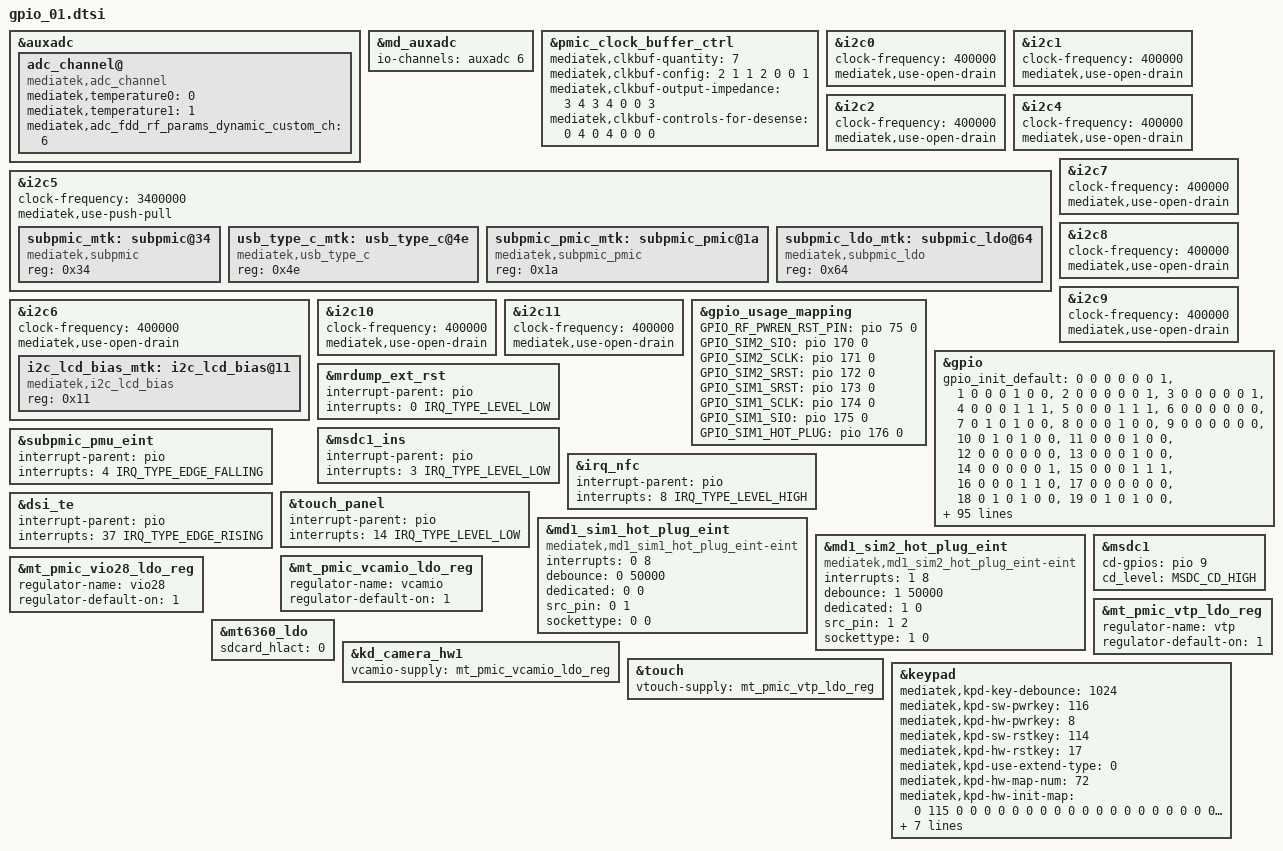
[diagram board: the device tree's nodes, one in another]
/*
 * Mediatek's mt6877 SoC device tree source
 *
 * Copyright (C) 2021 MediaTek Inc.
 *
 * This program is free software; you can redistribute it and/or modify
 * it under the terms of the GNU General Public License version 2 as
 * published by the Free Software Foundation.
 *
 * This program is distributed in the hope that it will be useful,
 * but WITHOUT ANY WARRANTY; without even the implied warranty of
 * MERCHANTABILITY or FITNESS FOR A PARTICULAR PURPOSE.
 * See http://www.gnu.org/licenses/gpl-2.0.html for more details.
 */
/*
 * Generated by MTK SP DrvGen Version: 3.5.160809 for MT6877.
 * 2021-09-27 17:35:26
 * Do Not Modify The File.
 * Copyright Mediatek Inc. (c) 2021.
 */

/*************************
 * ADC DTSI File
 *************************/

&auxadc {
	adc_channel@ {
		compatible = "mediatek,adc_channel";
		mediatek,temperature0 = <0>;
		mediatek,temperature1 = <1>;
		mediatek,adc_fdd_rf_params_dynamic_custom_ch = <6>;
		status = "okay";
	};
};
&md_auxadc {
	io-channels = <&auxadc 6>;
};


/*************************
 * CLK_BUF DTSI File
 *************************/

&pmic_clock_buffer_ctrl {
	mediatek,clkbuf-quantity = <7>;
	mediatek,clkbuf-config = <2 1 1 2 0 0 1>;
	mediatek,clkbuf-output-impedance = <3 4 3 4 0 0 3>;
	mediatek,clkbuf-controls-for-desense = <0 4 0 4 0 0 0>;
	status = "okay";
};


/*************************
 * I2C DTSI File
 *************************/

&i2c0 {
	#address-cells = <1>;
	#size-cells = <0>;
	clock-frequency = <400000>;
	mediatek,use-open-drain;
};

&i2c1 {
	#address-cells = <1>;
	#size-cells = <0>;
	clock-frequency = <400000>;
	mediatek,use-open-drain;
};

&i2c2 {
	#address-cells = <1>;
	#size-cells = <0>;
	clock-frequency = <400000>;
	mediatek,use-open-drain;
	// camera_main_two_mtk:camera_main_two@10 {
	// 	compatible = "mediatek,camera_main_two";
	// 	reg = <0x10>;
	// 	status = "okay";
	// };

	// camera_main_three_mtk:camera_main_three@10 {
	// 	compatible = "mediatek,camera_main_three";
	// 	reg = <0x10>;
	// 	status = "okay";
	// };

	// camera_main_three_af_mtk:camera_main_three_af@0c {
	// 	compatible = "mediatek,camera_main_three_af";
	// 	reg = <0x0c>;
	// 	status = "okay";
	// };

};

&i2c4 {
	#address-cells = <1>;
	#size-cells = <0>;
	clock-frequency = <400000>;
	mediatek,use-open-drain;
	// camera_sub_mtk:camera_sub@1a {
	// 	compatible = "mediatek,camera_sub";
	// 	reg = <0x1a>;
	// 	status = "okay";
	// };

	// camera_main_two_af_mtk:camera_main_two_af@0c {
	// 	compatible = "mediatek,camera_main_two_af";
	// 	reg = <0x0c>;
	// 	status = "okay";
	// };

};

&i2c5 {
	#address-cells = <1>;
	#size-cells = <0>;
	clock-frequency = <3400000>;
	mediatek,use-push-pull;
	subpmic_mtk:subpmic@34 {
		compatible = "mediatek,subpmic";
		reg = <0x34>;
		status = "okay";
	};

	usb_type_c_mtk:usb_type_c@4e {
		compatible = "mediatek,usb_type_c";
		reg = <0x4e>;
		status = "okay";
	};

	subpmic_pmic_mtk:subpmic_pmic@1a {
		compatible = "mediatek,subpmic_pmic";
		reg = <0x1a>;
		status = "okay";
	};

	subpmic_ldo_mtk:subpmic_ldo@64 {
		compatible = "mediatek,subpmic_ldo";
		reg = <0x64>;
		status = "okay";
	};

};

&i2c6 {
	#address-cells = <1>;
	#size-cells = <0>;
	clock-frequency = <400000>;
	mediatek,use-open-drain;
	i2c_lcd_bias_mtk:i2c_lcd_bias@11 {
		compatible = "mediatek,i2c_lcd_bias";
		reg = <0x11>;
		status = "okay";
	};

};

&i2c7 {
	#address-cells = <1>;
	#size-cells = <0>;
	clock-frequency = <400000>;
	mediatek,use-open-drain;
};

&i2c8 {
	#address-cells = <1>;
	#size-cells = <0>;
	clock-frequency = <400000>;
	mediatek,use-open-drain;
	// camera_main_mtk:camera_main@1a {
	// 	compatible = "mediatek,camera_main";
	// 	reg = <0x1a>;
	// 	status = "okay";
	// };

	// camera_main_af_mtk:camera_main_af@0e {
	// 	compatible = "mediatek,camera_main_af";
	// 	reg = <0x0e>;
	// 	status = "okay";
	// };

};

&i2c9 {
	#address-cells = <1>;
	#size-cells = <0>;
	clock-frequency = <400000>;
	mediatek,use-open-drain;
};

&i2c10 {
	#address-cells = <1>;
	#size-cells = <0>;
	clock-frequency = <400000>;
	mediatek,use-open-drain;
};

&i2c11 {
	#address-cells = <1>;
	#size-cells = <0>;
	clock-frequency = <400000>;
	mediatek,use-open-drain;
};



/*************************
 * GPIO DTSI File
 *************************/

&gpio_usage_mapping {
	GPIO_RF_PWREN_RST_PIN = <&pio 75 0>;
	GPIO_SIM2_SIO = <&pio 170 0>;
	GPIO_SIM2_SCLK = <&pio 171 0>;
	GPIO_SIM2_SRST = <&pio 172 0>;
	GPIO_SIM1_SRST = <&pio 173 0>;
	GPIO_SIM1_SCLK = <&pio 174 0>;
	GPIO_SIM1_SIO = <&pio 175 0>;
	GPIO_SIM1_HOT_PLUG = <&pio 176 0>;
};

&gpio{
	gpio_init_default = <0 0 0 0 0 0 1>,
		<1 0 0 0 1 0 0>,	/* EL_ON1_DET */
		<2 0 0 0 0 0 1>,
		<3 0 0 0 0 0 1>,
		<4 0 0 0 1 1 1>,
		<5 0 0 0 1 1 1>,
		<6 0 0 0 0 0 0>,
		<7 0 1 0 1 0 0>,
		<8 0 0 0 1 0 0>,	/* FG_ERR */
		<9 0 0 0 0 0 0>,
		<10 0 1 0 1 0 0>,
		<11 0 0 0 1 0 0>,
		<12 0 0 0 0 0 0>,
		<13 0 0 0 1 0 0>,
		<14 0 0 0 0 0 1>,
		<15 0 0 0 1 1 1>,
		<16 0 0 0 1 1 0>,
		<17 0 0 0 0 0 0>,
		<18 0 1 0 1 0 0>,
		<19 0 1 0 1 0 0>,
		<20 0 1 0 1 0 0>,
		<21 0 0 0 1 1 1>,
		<22 0 0 0 1 1 1>,
		<23 7 0 0 1 0 0>,
		<24 0 0 0 1 0 0>,
		<25 0 0 0 1 0 0>,
		<26 0 0 0 1 0 0>,
		<27 0 0 0 1 0 0>,
		<28 0 0 0 1 0 0>,
		<29 0 0 0 1 0 0>,
		<30 0 0 0 1 0 0>,
		<31 0 0 0 1 0 0>,
		<32 0 0 0 1 0 0>,
		<33 0 0 0 1 0 0>,
		<34 0 0 0 1 0 0>,
		<35 0 0 0 1 0 0>,
		<36 1 0 0 1 1 1>,
		<37 1 0 0 1 1 1>,
		<38 0 0 0 1 0 0>,
		<39 1 0 0 1 0 1>,
		<40 0 1 0 0 2 0>,	/* OCTA_RST_N */
		<41 1 0 0 0 0 1>,
		<42 1 0 0 0 0 1>,
		<43 1 0 0 1 0 1>,
		<44 1 0 0 1 0 1>,
		<45 1 0 0 1 0 1>,
		<46 1 0 0 0 0 0>,
		<47 1 0 0 0 0 0>,
		<48 1 0 0 0 0 0>,
		<49 1 0 0 0 0 0>,
		<50 1 0 0 1 0 0>,
		<51 1 0 0 1 0 0>,
		<52 1 0 0 1 0 0>,
		<53 1 0 0 1 0 0>,
		<54 1 0 0 1 0 1>,
		<55 1 0 0 1 0 0>,
		<56 1 0 0 1 0 0>,
		<57 1 0 0 1 0 0>,
		<58 1 0 0 1 0 0>,
		<59 1 0 0 1 0 0>,
		<60 1 0 0 0 0 1>,
		<61 1 0 0 0 0 1>,
		<62 0 0 0 1 0 0>,
		<63 0 0 0 1 0 0>,
		<64 1 0 0 1 1 1>,
		<65 1 0 0 1 1 1>,
		<66 1 0 0 1 0 1>,
		<67 1 0 0 1 0 1>,
		<68 1 0 0 0 0 0>,  /*MIPI_ANT2_SCLK*/
		<69 1 0 0 1 0 0>,  /*MIPI_ANT2_SDATA*/
		<70 1 0 0 1 0 1>,
		<71 0 0 0 0 0 0>,  /*CABLE_DET_MAIN1*/
		<72 0 0 0 0 0 0>,  /*CABLE_DET_MAIN2*/
		<73 1 0 0 1 0 0>,  /*DIV_BAND_SEL0*/
		<74 0 0 0 1 0 0>,
		<75 0 1 1 0 0 1>,
		<76 0 1 0 1 0 1>,
		<77 1 0 0 1 0 0>,  /*DIV_BAND_SEL1*/
		<78 1 0 0 1 0 0>,  /*DIV_BAND_5_8*/
		<79 0 0 0 1 0 0>,
		<80 0 0 0 1 0 0>,
		<81 0 0 0 1 0 0>,
		<82 1 0 0 0 0 0>,  /*MIPI_ANT1_SCLK*/
		<83 1 0 0 1 0 0>,  /*MIPI_ANT1_SDATA*/
		<84 1 0 0 0 0 0>,  /*MIPI_ANT0_SCLK*/
		<85 1 0 0 1 0 0>,  /*MIPI_ANT0_SDATA*/
		<86 1 0 0 1 0 1>,
		<87 0 0 0 1 0 0>,
		<88 0 0 0 1 0 0>,
		<89 0 0 0 1 0 0>,
		<90 0 0 0 0 0 1>,
		<91 0 0 0 1 0 0>,
		<92 0 0 0 1 0 0>,
		<93 0 0 0 1 0 0>,
		<94 0 1 0 1 0 1>,
		<95 0 0 0 1 0 0>,
		<96 0 1 0 1 0 1>,
		<97 0 1 0 1 0 1>,
		<98 1 0 0 0 0 0>,
		<99 1 0 0 0 0 0>,
		<100 1 0 0 1 0 0>,
		<101 1 0 0 0 0 0>,
		<102 0 0 0 1 0 0>,
		<103 1 0 0 0 0 0>,
		<104 1 0 0 0 0 0>,
		<105 1 0 0 1 0 0>,
		<106 1 0 0 0 0 0>,
		<107 0 1 0 0 0 1>,
		<108 0 0 0 1 0 0>,
		<109 0 1 0 1 0 0>,
		<110 0 1 1 0 0 0>,
		<111 0 1 0 1 0 1>,
		<112 0 0 0 1 0 0>,
		<113 0 0 0 1 0 0>,
		<114 1 0 0 1 1 0>,
		<115 2 0 0 1 0 0>,
		<116 1 0 0 1 1 1>,
		<117 0 1 0 1 0 0>,
		<118 0 0 0 0 2 0>,	/* UB_CON_DET */
		<119 0 1 0 0 2 0>,	/* LCD_3P0_EN */
		<120 0 0 0 1 0 0>,
		<121 0 1 0 1 0 0>,
		<122 7 0 0 1 0 1>,
		<123 7 0 0 1 0 0>,
		<124 7 0 0 1 0 0>,
		<125 7 0 0 1 0 0>,
		<126 2 0 0 0 0 0>,
		<127 2 0 0 0 0 0>,
		<128 2 0 0 0 0 1>,
		<129 2 0 0 1 0 1>,
		<130 2 0 0 1 1 1>,
		<131 2 0 0 1 1 1>,
		<132 1 0 0 1 1 1>,
		<133 1 0 0 1 1 1>,
		<134 1 0 0 1 1 1>,
		<135 1 0 0 1 1 1>,
		<136 1 0 0 1 1 1>,
		<137 1 0 0 1 1 1>,
		<138 0 0 0 1 0 0>,
		<139 0 0 0 1 0 0>,
		<140 0 1 0 1 0 1>,
		<141 0 1 0 1 0 1>,
		<142 0 1 0 1 0 1>,
		<143 1 0 0 1 1 1>,
		<144 1 0 0 1 1 1>,
		<145 1 0 0 1 1 1>,
		<146 1 0 0 1 1 1>,
		<147 1 0 0 1 1 1>,
		<148 1 0 0 1 1 1>,
		<149 1 1 0 0 0 1>,
		<150 1 1 0 0 0 1>,
		<151 1 1 0 0 0 1>,
		<152 1 1 0 0 0 1>,
		<153 1 1 0 0 0 1>,
		<154 0 1 0 1 0 0>,
		<155 0 1 0 1 0 0>,
		<156 3 0 0 0 0 0>,
		<157 3 0 0 0 0 0>,
		<158 0 0 0 1 0 0>,
		<159 0 1 0 1 0 0>,
		<160 0 0 0 1 0 0>,
		<161 0 1 0 1 0 0>,
		<162 0 0 0 1 0 0>,
		<163 0 1 0 1 0 0>,
		<164 1 0 0 1 1 0>,
		<165 1 0 0 0 0 0>,
		<166 1 0 0 1 1 0>,
		<167 1 0 0 1 1 0>,
		<168 1 0 0 1 1 0>,
		<169 1 0 0 1 1 0>,
		<170 1 0 0 1 1 1>,
		<171 1 0 0 0 0 1>,
		<172 1 0 0 0 0 1>,
		<173 1 0 0 0 0 1>,
		<174 1 0 0 0 0 1>,
		<175 1 0 0 1 1 1>,
		<176 1 0 0 0 0 1>,
		<177 0 0 0 1 0 0>,
		<178 1 0 0 0 0 0>,
		<179 1 0 0 1 1 0>,
		<180 0 0 0 1 0 0>,
		<181 0 0 0 1 0 0>,
		<182 0 0 0 1 0 0>,
		<183 0 0 0 1 0 0>,
		<184 0 0 0 1 0 0>,
		<185 0 0 0 1 0 0>,
		<186 1 0 0 0 1 1>,
		<187 1 0 0 0 1 1>,
		<188 4 0 0 1 0 0>,
		<189 0 0 0 1 0 0>,
		<190 0 0 0 1 0 0>,
		<191 5 0 0 0 0 0>,
		<192 5 0 0 0 0 0>,
		<193 0 0 0 1 0 0>,
		<194 0 0 0 1 0 0>,
		<195 0 0 0 1 0 0>,
		<196 1 0 0 1 0 0>,
		<197 1 0 0 1 0 0>,
		<198 1 0 0 1 0 0>,
		<199 1 0 0 1 0 0>,
		<200 1 0 0 1 0 0>,
		<201 1 0 0 1 0 0>,
		<202 1 0 0 1 0 0>,
		<203 1 0 0 1 0 0>,
		<204 1 0 0 1 0 0>,
		<205 0 0 0 1 0 0>,
		<206 0 0 0 1 0 0>,
		<207 0 0 0 1 0 0>,
		<208 0 0 0 1 0 0>;
};


/*************************
 * EINT DTSI File
 *************************/

#include <dt-bindings/interrupt-controller/irq.h>
#include <dt-bindings/interrupt-controller/arm-gic.h>
#include <dt-bindings/mmc/mt6877-msdc.h>

&mrdump_ext_rst {
	interrupt-parent = <&pio>;
	interrupts = <0 IRQ_TYPE_LEVEL_LOW>;
	status = "okay";
};

&msdc1_ins {
	interrupt-parent = <&pio>;
	interrupts = <3 IRQ_TYPE_LEVEL_LOW>;
	status = "okay";
};

&subpmic_pmu_eint {
	interrupt-parent = <&pio>;
	interrupts = <4 IRQ_TYPE_EDGE_FALLING>;
	status = "okay";
};

&irq_nfc {
	interrupt-parent = <&pio>;
	interrupts = <8 IRQ_TYPE_LEVEL_HIGH>;
	status = "okay";
};

&touch_panel {
	interrupt-parent = <&pio>;
	interrupts = <14 IRQ_TYPE_LEVEL_LOW>;
	status = "okay";
};

&dsi_te {
	interrupt-parent = <&pio>;
	interrupts = <37 IRQ_TYPE_EDGE_RISING>;
	status = "okay";
};



/*************************
 * MD1_EINT DTSI File
 *************************/

&md1_sim1_hot_plug_eint {
	compatible = "mediatek,md1_sim1_hot_plug_eint-eint";
	interrupts = <0 8>;
	debounce = <0 50000>;
	dedicated = <0 0>;
	src_pin = <0 1>;
	sockettype = <0 0>;
	status = "okay";
};

&md1_sim2_hot_plug_eint {
	compatible = "mediatek,md1_sim2_hot_plug_eint-eint";
	interrupts = <1 8>;
	debounce = <1 50000>;
	dedicated = <1 0>;
	src_pin = <1 2>;
	sockettype = <1 0>;
	status = "okay";
};

&msdc1 {
	cd-gpios = <&pio 9 0>;
	cd_level = /bits/ 8 <MSDC_CD_HIGH>;
};

/*************************
 * PMIC DTSI File
 *************************/

&mt_pmic_vcamio_ldo_reg {
	regulator-name = "vcamio";
	regulator-default-on = <1>; /* 0:skip, 1: off, 2:on */
	status = "okay";
};

&mt_pmic_vio28_ldo_reg {
	regulator-name = "vio28";
	regulator-default-on = <1>; /* 0:skip, 1: off, 2:on */
	status = "okay";
};

&mt_pmic_vtp_ldo_reg {
	regulator-name = "vtp";
	regulator-default-on = <1>; /* 0:skip, 1: off, 2:on */
	status = "okay";
};

&mt6360_ldo {
	sdcard_hlact = <0>;
};

&kd_camera_hw1 {
	vcamio-supply = <&mt_pmic_vcamio_ldo_reg>;
	status = "okay";
};

&touch {
	vtouch-supply = <&mt_pmic_vtp_ldo_reg>;
	status = "okay";
};


/*************************
 * POWER DTSI File
 *************************/



/*************************
 * KPD DTSI File
 *************************/

&keypad {
	mediatek,kpd-key-debounce = <1024>;
	mediatek,kpd-sw-pwrkey = <116>;
	mediatek,kpd-hw-pwrkey = <8>;
	mediatek,kpd-sw-rstkey  = <114>;
	mediatek,kpd-hw-rstkey = <17>;
	mediatek,kpd-use-extend-type = <0>;
	/*HW Keycode [0~71] -> Linux Keycode*/
	mediatek,kpd-hw-map-num = <72>;
	mediatek,kpd-hw-init-map = <0 115 0 0 0 0 0 0 0 0 0 0 0 0 0 0 0 0 0 0
	0 0 0 0 0 0 0 0 0 0 0 0 0 0 0 0 0 0 0 0 0 0 0 0 0 0 0 0 0 0 0 0 0 0 0
	0 0 0 0 0 0 0 0 0 0 0 0 0 0 0 0 0 >;
	mediatek,kpd-pwrkey-eint-gpio = <0>;
	mediatek,kpd-pwkey-gpio-din  = <0>;
	mediatek,kpd-hw-dl-key0 = <17>;
	mediatek,kpd-hw-dl-key1 = <0>;
	mediatek,kpd-hw-dl-key2 = <8>;
	mediatek,kpd-hw-recovery-key = <17>;
	mediatek,kpd-hw-factory-key = <0>;
	status = "okay";
};


